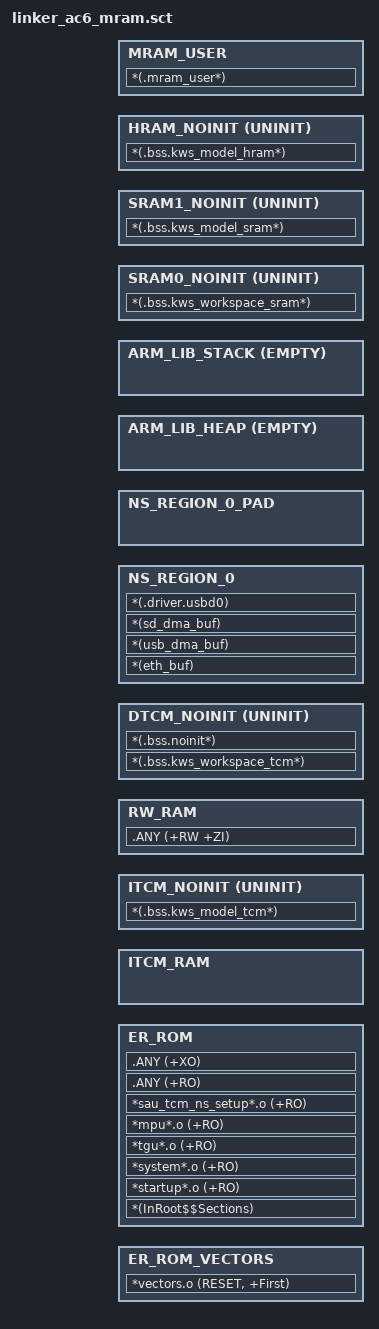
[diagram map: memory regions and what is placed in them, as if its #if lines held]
#! armclang -E --target=arm-arm-none-eabi -mcpu=cortex-m55 -xc
; command above MUST be in first line (no comment above!)

#include "app_mem_regions.h"

#define __ROM_BASE      APP_MRAM_HE_BASE
#define __ROM_SIZE      APP_MRAM_HE_SIZE

#define __ITCM_BASE     APP_ITCM_BASE
#define __ITCM_SIZE     APP_HE_ITCM_SIZE

#define __RAM_BASE      APP_DTCM_BASE
#define __RAM_SIZE      APP_HE_DTCM_SIZE

#define __STACK_SIZE    APP_HE_STACK_SIZE
#define __HEAP_SIZE     APP_HE_HEAP_SIZE

/*----------------------------------------------------------------------------
  User Stack & Heap boundary definition
 *----------------------------------------------------------------------------*/
#define __STACK_TOP     (__RAM_BASE + __RAM_SIZE)    /* starts at end of RAM */
#define __HEAP_BASE     (AlignExpr(+0, 8))           /* starts after RW_RAM section, 8 byte aligned */

/*----------------------------------------------------------------------------
  Scatter File Definitions definition
 *----------------------------------------------------------------------------*/

#define __RW_BASE       __RAM_BASE
#define __RW_SIZE      (__RAM_SIZE - __STACK_SIZE - __HEAP_SIZE)

LR_ROM __ROM_BASE __ROM_SIZE {
  ER_ROM_VECTORS (AlignExpr(__ROM_BASE, 2048)) {
    *vectors.o (RESET, +First)
  }

  ER_ROM (AlignExpr(+0, 16)) {
    *(InRoot$$Sections)

    *startup*.o (+RO)
    *system*.o (+RO)
    *tgu*.o (+RO)
    *mpu*.o (+RO)
    *sau_tcm_ns_setup*.o (+RO)

    .ANY (+RO)
    .ANY (+XO)
  }

  ITCM_RAM __ITCM_BASE __ITCM_SIZE {
  }

  ITCM_NOINIT (AlignExpr(+0, 16)) UNINIT {
    *(.bss.kws_model_tcm*)
  }

  RW_RAM __RW_BASE __RW_SIZE {
    .ANY (+RW +ZI)
  }

  DTCM_NOINIT (AlignExpr(+0, 16)) UNINIT {
    *(.bss.kws_workspace_tcm*)
    *(.bss.noinit*)
  }

  NS_REGION_0 (AlignExpr(+0, TGU_BLOCK_SIZE)) {
    *(eth_buf)
    *(usb_dma_buf)
    *(sd_dma_buf)
    *(.driver.usbd0)
  }
  NS_REGION_0_PAD  (AlignExpr(ImageLimit(NS_REGION_0), TGU_BLOCK_SIZE)) {}
  ScatterAssert((ImageBase(NS_REGION_0_PAD) - ImageBase(NS_REGION_0) + ImageLength(RW_RAM)) < __RW_SIZE)

#if __HEAP_SIZE > 0
  ARM_LIB_HEAP __HEAP_BASE EMPTY __HEAP_SIZE {}
#endif
  ARM_LIB_STACK __STACK_TOP EMPTY -__STACK_SIZE {}

#if __HAS_BULK_SRAM
  SRAM0_NOINIT (AlignExpr(+0, 16)) UNINIT {
    *(.bss.kws_workspace_sram*)
  }
  SRAM1_NOINIT (AlignExpr(+0, 16)) UNINIT {
    *(.bss.kws_model_sram*)
  }
#endif

#if __HAS_HYPER_RAM
  HRAM_NOINIT APP_HRAM_HE_BASE UNINIT APP_HRAM_HE_SIZE {
    *(.bss.kws_model_hram*)
  }
#endif

  MRAM_USER  APP_MRAM_USER_BASE  APP_MRAM_USER_SIZE  {
   *(.mram_user*)
  }
}
